# M031AE_v1 register map
File version: 1.0
M031AE_v1 SVD file
Registers are 32-bit, read-write, reset 0x0 unless marked. A register's access mark holds for its fields unless they carry their own. Offsets are from the block's base; lines under a group give offsets from that group; [hi:lo] are bit positions; {n}, {i} and the like mark numbered series; 'fields as' and 'values as' point back to an identical list; <NAME> marks a mode.

## Memory map
0x40000000 SYS blocks up to offset 0x1F0 — SYS Register Map
0x40000200 CLK blocks up to offset 0xB8 — CLK Register Map
0x40000300 NMI size 0x8 — NMI Register Map
0x40004000 GPIO blocks up to offset 0x9F0 — GPIO Register Map
0x40008000 PDMA blocks up to offset 0x48C — PDMA Register Map
0x4000C000 FMC blocks up to offset 0xC8 — FMC Register Map
0x40010000 EBI blocks up to offset 0x18 — EBI Register Map
0x40014000 HDIV size 0x14 — HDIV Register Map
0x40031000 CRC size 0x10 — CRC Register Map
0x40040000 WDT size 0xC — WDT Register Map
0x40040100 WWDT size 0x10 — WWDT Register Map
0x40041000 RTC blocks up to offset 0x104 — RTC Register Map
0x40043000 ADC blocks up to offset 0x188 — ADC Register Map
0x40045000 ACMP01 size 0x18 — ACMP Register Map
0x40050000 TMR01 blocks up to offset 0x3C — TIMER Register Map
0x40051000 TMR23 blocks up to offset 0x3C — TIMER Register Map
0x40058000 PWM0 blocks up to offset 0x334 — PWM Register Map
0x40059000 PWM1 blocks up to offset 0x334 — PWM Register Map
0x4005A000 BPWM0 blocks up to offset 0x334 — BPWM Register Map
0x4005B000 BPWM1 blocks up to offset 0x334 — BPWM Register Map
0x40060000 QSPIx blocks up to offset 0x34 — QSPI Register Map
0x40061000 SPIx blocks up to offset 0x6C — SPI Register Map
{0x40070000+0x1000*n} UART{n} blocks up to offset 0x4C (n=0..7) — UART Register Map
0x40080000 I2C0 blocks up to offset 0x6C — I2C Register Map
0x40081000 I2C1 blocks up to offset 0x6C — I2C Register Map
0x400C0000 USBD blocks up to offset 0x580 — USBD Register Map
0x400D0000 UUART0 blocks up to offset 0x68 — USCIUART Register Map
0x400D0000 USPI0 blocks up to offset 0x68 — USCISPI Register Map
0x400D0000 UI2C0 blocks up to offset 0x90 — UI2CI2C Register Map
0x400D1000 UUART1 blocks up to offset 0x68 — USCIUART Register Map
0x400D1000 USPI1 blocks up to offset 0x68 — USCISPI Register Map
0x400D1000 UI2C1 blocks up to offset 0x90 — UI2CI2C Register Map
0xE000E000 SCS blocks up to offset 0xD24 — SYST_SCR Register Map
0xE000E100 NVIC blocks up to offset 0x204 — NVIC Register Map

## NVIC — NVIC Register Map
Base 0xE000E100
0x00 NVIC_ISER0 — IRQ0 ~ IRQ31 Set-enable Control Register
  [31:0] SETENA — Interrupt Set Enable Bit. The NVIC_ISER0 registers enable interrupts, and show which interrupts are enabled. Write Operation:
    0=No effect. Interrupt Disabled; 1=Interrupt Enabled
0x80 NVIC_ICER0 — IRQ0 ~ IRQ31 Clear-enable Control Register
  [31:0] CALENA — Interrupt Clear Enable Bit. The NVIC_ICER0 registers disable interrupts, and show which interrupts are enabled. Write Operation:
    0=No effect. Interrupt Disabled; 1=Interrupt Disabled. Interrupt Enabled
0x100 NVIC_ISPR0 — IRQ0 ~ IRQ31 Set-pending Control Register
  [31:0] SETPEND — Interrupt Set-pending. The NVIC_ISPR0 registers force interrupts into the pending state, and show which interrupts are pending. Write Operation:
    0=No effect. Interrupt is not pending; 1=Changes interrupt state to pending. Interrupt is pending
0x180 NVIC_ICPR0 — IRQ0 ~ IRQ31 Clear-pending Control Register
  [31:0] CALPEND — Interrupt Clear-pending. The NVIC_ICPR0 registers remove the pending state from interrupts, and show which interrupts are pending. Write Operation:
    0=No effect. Interrupt is not pending; 1=Removes pending state an interrupt. Interrupt is pending
0x200 NVIC_IABR0 — IRQ0 ~ IRQ31 Active Bit Register
  [31:0] ACTIVE — Interrupt Active Flags. The NVIC_IABR0 registers indicate which interrupts are active.
    0=interrupt not active; 1=interrupt active

## WWDT — WWDT Register Map
Base 0x40040100
0x00 WWDT_RLDCNT wo — WWDT Reload Counter Register
  [31:0] RLDCNT — WWDT Reload Counter Register. Writing 0x00005AA5 to this register will reload the WWDT counter value to 0x3F. Note: User can only write WWDT_RLDCNT register to reload WWDT counter value when current WWDT counter value between 0 and CMPDAT (WWDT_CTL[21:16]). If user writes WWDT_RLDCNT when current WWDT counter value is larger than CMPDAT, WWDT reset signal will be generated immediately.
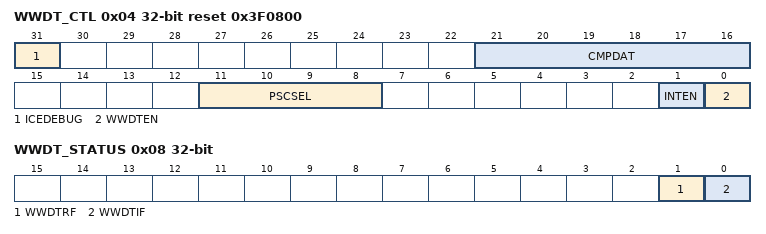
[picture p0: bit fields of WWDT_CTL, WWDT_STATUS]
0x04 WWDT_CTL reset 0x3F0800 — WWDT Control Register
  [31] ICEDEBUG — ICE Debug Mode Acknowledge Disable Bit. Note: WWDT down counter will keep going no matter CPU is held by ICE or not.
    0=ICE debug mode acknowledgement effects WWDT counting; 1=ICE debug mode acknowledgement Disabled
  [21:16] CMPDAT — WWDT Window Compare Register. Set this register to adjust the valid reload window. Note: User can only write WWDT_RLDCNT register to reload WWDT counter value when current WWDT counter value between 0 and CMPDAT. If user writes WWDT_RLDCNT register when current WWDT counter value larger than CMPDAT, WWDT reset signal will generate immediately.
  [11:8] PSCSEL — WWDT Counter Prescale Period Selection
    0=Pre-scale is 1; Max time-out period is 1 * 64 * WWDT_CLK; 1=Pre-scale is 2; Max time-out period is 2 * 64 * WWDT_CLK; 2=Pre-scale is 4; Max time-out period is 4 * 64 * WWDT_CLK; 3=Pre-scale is 8; Max time-out period is 8 * 64 * WWDT_CLK; 4=Pre-scale is 16; Max time-out period is 16 * 64 * WWDT_CLK; 5=Pre-scale is 32; Max time-out period is 32 * 64 * WWDT_CLK; 6=Pre-scale is 64; Max time-out period is 64 * 64 * WWDT_CLK; 7=Pre-scale is 128; Max time-out period is 128 * 64 * WWDT_CLK; 8=Pre-scale is 192; Max time-out period is 192 * 64 * WWDT_CLK; 9=Pre-scale is 256; Max time-out period is 256 * 64 * WWDT_CLK; 10=Pre-scale is 384; Max time-out period is 384 * 64 * WWDT_CLK; 11=Pre-scale is 512; Max time-out period is 512 * 64 * WWDT_CLK; 12=Pre-scale is 768; Max time-out period is 768 * 64 * WWDT_CLK; 13=Pre-scale is 1024; Max time-out period is 1024 * 64 * WWDT_CLK; 14=Pre-scale is 1536; Max time-out period is 1536 * 64 * WWDT_CLK; 15=Pre-scale is 2048; Max time-out period is 2048 * 64 * WWDT_CLK
  [1] INTEN — WWDT Interrupt Enable Bit. If this bit is enabled, the WWDT counter compare match interrupt signal is generated and inform to CPU.
    0=WWDT counter compare match interrupt Disabled; 1=WWDT counter compare match interrupt Enabled
  [0] WWDTEN — WWDT Enable Bit
    0=WWDT counter is stopped; 1=WWDT counter starts counting
0x08 WWDT_STATUS
  [1] WWDTRF — WWDT Timer-out Reset Flag. This bit indicates the system has been reset by WWDT time-out reset or not. Note: This bit is cleared by writing 1 to it.
    0=WWDT time-out reset did not occur; 1=WWDT time-out reset occurred
  [0] WWDTIF — WWDT Compare Match Interrupt Flag. This bit indicates the interrupt flag status of WWDT while WWDT counter value matches CMPDAT (WWDT_CTL[21:16]). Note: This bit is cleared by writing 1 to it.
    0=No effect; 1=WWDT counter value matches CMPDAT
0x0C WWDT_CNT ro reset 0x3F — WWDT Counter Value Register
  [5:0] CNTDAT — WWDT Counter Value. CNTDAT will be updated continuously to monitor 6-bit WWDT down counter value.
